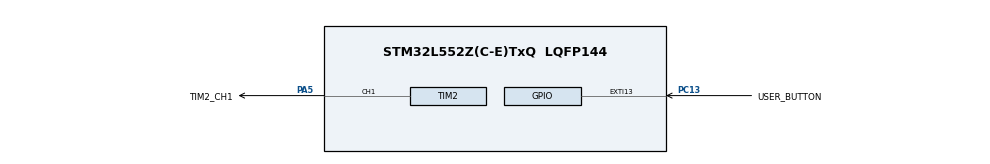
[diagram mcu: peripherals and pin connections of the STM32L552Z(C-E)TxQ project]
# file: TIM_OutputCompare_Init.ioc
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Mcu.Family=STM32L5
Mcu.Name=STM32L552Z(C-E)TxQ
Mcu.Package=LQFP144
Mcu.TrustZone=disable
NVIC.EXTI13_IRQn=true\:0\:0\:false\:false\:true\:true\:true\:true
NVIC.PriorityGroup=NVIC_PRIORITYGROUP_3
NVIC.TIM2_IRQn=true\:0\:0\:false\:false\:true\:true\:true\:true
PA5.GPIO_Label=TIM2_CH1
PA5.Signal=S_TIM2_CH1
PC13.GPIO_Label=USER_BUTTON
PC13.GPIO_ModeDefaultEXTI=GPIO_MODE_IT_FALLING
PC13.GPIO_PuPd=GPIO_PULLDOWN
PC13.Signal=GPXTI13
ProjectManager.HeapSize=0x200
ProjectManager.StackSize=0x400
ProjectManager.TargetToolchain=EWARM V8.32
RCC.ADCCLockSelection=RCC_ADCCLKSOURCE_SYSCLK
RCC.ADCFreq_Value=110000000
RCC.AHBFreq_Value=110000000
RCC.APB1Freq_Value=110000000
RCC.APB1TimFreq_Value=110000000
RCC.APB2Freq_Value=110000000
RCC.APB2TimFreq_Value=110000000
RCC.CortexFreq_Value=110000000
RCC.HCLKFreq_Value=110000000
RCC.HSE_VALUE=16000000
RCC.HSI48_VALUE=48000000
RCC.HSI_VALUE=16000000
RCC.LSE_VALUE=32768
RCC.MSI_VALUE=4000000
RCC.PLLN=55
RCC.PLLSAI1N=24
RCC.RTCClockSelection=RCC_RTCCLKSOURCE_LSE
RCC.SYSCLKFreq_VALUE=110000000
RCC.SYSCLKSource=RCC_SYSCLKSOURCE_PLLCLK
RCC.USBFreq_Value=48000000
RCC.VCOOutputFreq_Value=220000000
SH.S_TIM2_CH1.0=TIM2_CH1,Output Compare1 CH1
TIM2.AutoReloadPreload=TIM_AUTORELOAD_PRELOAD_DISABLE
TIM2.Channel-Output\ Compare1\ CH1=TIM_CHANNEL_1
TIM2.ClearInputSource=TIM_CLEARINPUTSOURCE_NONE
TIM2.ClockDivision=TIM_CLOCKDIVISION_DIV1
TIM2.CounterMode=TIM_COUNTERMODE_UP
TIM2.OC1Preload=DISABLE
TIM2.OCMode_1=TIM_OCMODE_TOGGLE
TIM2.OCPolarity_1=TIM_OCPOLARITY_HIGH
TIM2.Period=tim_period
TIM2.Prescaler=tim_prescaler
TIM2.Pulse-Output\ Compare1\ CH1=tim_pulse_value
TIM2.TIM_MasterOutputTrigger=TIM_TRGO_RESET
TIM2.TIM_MasterSlaveMode=TIM_MASTERSLAVEMODE_DISABLE
VP_ICACHE_VS_ICACHE.Mode=DirectMappedCache
VP_PWR_VS_DBSignals.Mode=DisableDeadBatterySignals
board=custom

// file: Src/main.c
/* USER CODE BEGIN Header */
/**
  ******************************************************************************
  * @file    Examples_LL/TIM/TIM_OutputCompare_Init/Src/main.c
  * @author  MCD Application Team
  * @brief   This example describes how to use a timer instance in output
  *          compare mode using the STM32L5xx TIM LL API.
  *          Peripheral initialization done using LL unitary services functions.
  ******************************************************************************
  * @attention
  *
  * Copyright (c) 2019 STMicroelectronics.
  * All rights reserved.
  *
  * This software is licensed under terms that can be found in the LICENSE file
  * in the root directory of this software component.
  * If no LICENSE file comes with this software, it is provided AS-IS.
  *
  ******************************************************************************
  */
/* USER CODE END Header */
#include "main.h"

/* USER CODE BEGIN PD */
/* Number of output compare modes */
#define TIM_OC_MODES_NB 3
/* USER CODE END PD */

/* USER CODE BEGIN PV */
/* Output compare modes */
static uint32_t aOCMode[TIM_OC_MODES_NB] = {
  LL_TIM_OCMODE_TOGGLE,
  LL_TIM_OCMODE_ACTIVE,
  LL_TIM_OCMODE_INACTIVE
};

/* Output compare mode index */
static uint8_t iOCMode = 0;

/* Compare match count */
static uint32_t uwCompareMatchCount = 0;

/* TIM2 Clock */
static uint32_t TimOutClock = 1;
static uint32_t tim_prescaler = 0;
static uint32_t tim_period = 0;
static uint32_t tim_pulse_value = 0;
/* USER CODE END PV */

void SystemClock_Config(void);
static void MX_GPIO_Init(void);
static void MX_ICACHE_Init(void);
static void MX_TIM2_Init(void);
/* USER CODE BEGIN PFP */
__STATIC_INLINE void     Configure_OCMode(uint32_t OCMode);
/* USER CODE END PFP */

int main(void)
{

  /* MCU Configuration--------------------------------------------------------*/

  /* Reset of all peripherals, Initializes the Flash interface and the Systick. */
  LL_APB2_GRP1_EnableClock(LL_APB2_GRP1_PERIPH_SYSCFG);
  LL_APB1_GRP1_EnableClock(LL_APB1_GRP1_PERIPH_PWR);

  /* System interrupt init*/
  NVIC_SetPriorityGrouping(NVIC_PRIORITYGROUP_3);

  /** Disable the internal Pull-Up in Dead Battery pins of UCPD peripheral
  */
  LL_PWR_DisableUCPDDeadBattery();

  /* Configure the system clock */
  SystemClock_Config();

  /* USER CODE BEGIN SysInit */

  /* Set the pre-scaler value to have TIM2 counter clock equal to 10 kHz */
  tim_prescaler = __LL_TIM_CALC_PSC(SystemCoreClock, 10000);

  /* Set the auto-reload value to have a counter frequency of 10 Hz */
  /* TIM2CLK = SystemCoreClock / (APB prescaler & multiplier)               */
  TimOutClock = SystemCoreClock/1;
  tim_period = __LL_TIM_CALC_ARR(TimOutClock, tim_prescaler, 10);

  /* Set output compare active/inactive delay to half of the auto-reload value */
  tim_pulse_value = tim_period / 2;

  /* USER CODE END SysInit */

  /* Initialize all configured peripherals */
  MX_GPIO_Init();
  MX_ICACHE_Init();
  MX_TIM2_Init();
  /* USER CODE BEGIN 2 */

  /**************************/
  /* TIM2 interrupts set-up */
  /**************************/
  /* Enable the capture/compare interrupt for channel 1*/
  LL_TIM_EnableIT_CC1(TIM2);

  /**********************************/
  /* Start output signal generation */
  /**********************************/
  /* Enable output channel 1 */
  LL_TIM_CC_EnableChannel(TIM2, LL_TIM_CHANNEL_CH1);

  /* Enable counter */
  LL_TIM_EnableCounter(TIM2);

  /* USER CODE END 2 */

  /* Infinite loop */
  while (1)
  {

  }
}

void SystemClock_Config(void)
{
  LL_FLASH_SetLatency(LL_FLASH_LATENCY_5);
  while(LL_FLASH_GetLatency()!= LL_FLASH_LATENCY_5)
  {
  }

  LL_PWR_SetRegulVoltageScaling(LL_PWR_REGU_VOLTAGE_SCALE0);
  LL_RCC_MSI_Enable();

   /* Wait till MSI is ready */
  while(LL_RCC_MSI_IsReady() != 1)
  {
  }

  LL_RCC_MSI_EnableRangeSelection();
  LL_RCC_MSI_SetRange(LL_RCC_MSIRANGE_6);
  LL_RCC_MSI_SetCalibTrimming(0);
  LL_RCC_PLL_ConfigDomain_SYS(LL_RCC_PLLSOURCE_MSI, LL_RCC_PLLM_DIV_1, 55, LL_RCC_PLLR_DIV_2);
  LL_RCC_PLL_EnableDomain_SYS();
  LL_RCC_PLL_Enable();

   /* Wait till PLL is ready */
  while(LL_RCC_PLL_IsReady() != 1)
  {
  }

   /* Intermediate AHB prescaler 2 when target frequency clock is higher than 80 MHz */
   LL_RCC_SetAHBPrescaler(LL_RCC_SYSCLK_DIV_2);

  LL_RCC_SetSysClkSource(LL_RCC_SYS_CLKSOURCE_PLL);

   /* Wait till System clock is ready */
  while(LL_RCC_GetSysClkSource() != LL_RCC_SYS_CLKSOURCE_STATUS_PLL)
  {
  }

  /* Insure 1us transition state at intermediate medium speed clock*/
  for (__IO uint32_t i = (RCC_MAX_FREQUENCY_MHZ >> 1); i !=0; i--);

  LL_RCC_SetAHBPrescaler(LL_RCC_SYSCLK_DIV_1);
  LL_RCC_SetAPB1Prescaler(LL_RCC_APB1_DIV_1);
  LL_RCC_SetAPB2Prescaler(LL_RCC_APB2_DIV_1);

  LL_Init1msTick(110000000);

  LL_SetSystemCoreClock(110000000);
}

static void MX_ICACHE_Init(void)
{

  /** Enable instruction cache in 1-way (direct mapped cache)
  */
  LL_ICACHE_SetMode(LL_ICACHE_1WAY);
  LL_ICACHE_Enable();

}

static void MX_TIM2_Init(void)
{

  LL_TIM_InitTypeDef TIM_InitStruct = {0};
  LL_TIM_OC_InitTypeDef TIM_OC_InitStruct = {0};

  LL_GPIO_InitTypeDef GPIO_InitStruct = {0};

  /* Peripheral clock enable */
  LL_APB1_GRP1_EnableClock(LL_APB1_GRP1_PERIPH_TIM2);

  /* TIM2 interrupt Init */
  NVIC_SetPriority(TIM2_IRQn, NVIC_EncodePriority(NVIC_GetPriorityGrouping(),0, 0));
  NVIC_EnableIRQ(TIM2_IRQn);

  TIM_InitStruct.Prescaler = tim_prescaler;
  TIM_InitStruct.CounterMode = LL_TIM_COUNTERMODE_UP;
  TIM_InitStruct.Autoreload = tim_period;
  TIM_InitStruct.ClockDivision = LL_TIM_CLOCKDIVISION_DIV1;
  LL_TIM_Init(TIM2, &TIM_InitStruct);
  LL_TIM_DisableARRPreload(TIM2);
  TIM_OC_InitStruct.OCMode = LL_TIM_OCMODE_TOGGLE;
  TIM_OC_InitStruct.OCState = LL_TIM_OCSTATE_DISABLE;
  TIM_OC_InitStruct.OCNState = LL_TIM_OCSTATE_DISABLE;
  TIM_OC_InitStruct.CompareValue = tim_pulse_value;
  TIM_OC_InitStruct.OCPolarity = LL_TIM_OCPOLARITY_HIGH;
  LL_TIM_OC_Init(TIM2, LL_TIM_CHANNEL_CH1, &TIM_OC_InitStruct);
  LL_TIM_OC_DisableFast(TIM2, LL_TIM_CHANNEL_CH1);
  LL_TIM_SetTriggerOutput(TIM2, LL_TIM_TRGO_RESET);
  LL_TIM_DisableMasterSlaveMode(TIM2);
  LL_AHB2_GRP1_EnableClock(LL_AHB2_GRP1_PERIPH_GPIOA);
  /**TIM2 GPIO Configuration
  PA5   ------> TIM2_CH1
  */
  GPIO_InitStruct.Pin = TIM2_CH1_Pin;
  GPIO_InitStruct.Mode = LL_GPIO_MODE_ALTERNATE;
  GPIO_InitStruct.Speed = LL_GPIO_SPEED_FREQ_LOW;
  GPIO_InitStruct.OutputType = LL_GPIO_OUTPUT_PUSHPULL;
  GPIO_InitStruct.Pull = LL_GPIO_PULL_NO;
  GPIO_InitStruct.Alternate = LL_GPIO_AF_1;
  LL_GPIO_Init(TIM2_CH1_GPIO_Port, &GPIO_InitStruct);

}

static void MX_GPIO_Init(void)
{
  LL_EXTI_InitTypeDef EXTI_InitStruct = {0};

  /* GPIO Ports Clock Enable */
  LL_AHB2_GRP1_EnableClock(LL_AHB2_GRP1_PERIPH_GPIOC);
  LL_AHB2_GRP1_EnableClock(LL_AHB2_GRP1_PERIPH_GPIOA);

  /**/
  LL_EXTI_SetEXTISource(LL_EXTI_EXTI_PORTC, LL_EXTI_EXTI_LINE13);

  /**/
  EXTI_InitStruct.Line_0_31 = LL_EXTI_LINE_13;
  EXTI_InitStruct.Line_32_63 = LL_EXTI_LINE_NONE;
  EXTI_InitStruct.LineCommand = ENABLE;
  EXTI_InitStruct.Mode = LL_EXTI_MODE_IT;
  EXTI_InitStruct.Trigger = LL_EXTI_TRIGGER_FALLING;
  LL_EXTI_Init(&EXTI_InitStruct);

  /**/
  LL_GPIO_SetPinPull(USER_BUTTON_GPIO_Port, USER_BUTTON_Pin, LL_GPIO_PULL_DOWN);

  /**/
  LL_GPIO_SetPinMode(USER_BUTTON_GPIO_Port, USER_BUTTON_Pin, LL_GPIO_MODE_INPUT);

  /* EXTI interrupt init*/
  NVIC_SetPriority(EXTI13_IRQn, NVIC_EncodePriority(NVIC_GetPriorityGrouping(),0, 0));
  NVIC_EnableIRQ(EXTI13_IRQn);

}

/* USER CODE BEGIN 4 */

/**
  * @brief  Changes the output compare mode.
  * @param  None
  * @retval None
  */
__STATIC_INLINE void Configure_OCMode(uint32_t OCMode)
{
  /* Disable the counter */
  LL_TIM_DisableCounter(TIM2);

  /* Reset the counter */
  LL_TIM_SetCounter(TIM2, 0);

  /* Reset the compare match count */
  uwCompareMatchCount = 0;

  /* Set the output level (active v.s. inactive) according to the new OC mode */
  switch (OCMode)
  {
    case LL_TIM_OCMODE_TOGGLE:
    case LL_TIM_OCMODE_ACTIVE:
      /* Set the output channel to its inactive level (LOW)*/
      LL_TIM_OC_SetMode(TIM2, LL_TIM_CHANNEL_CH1, LL_TIM_OCMODE_FORCED_INACTIVE);
      break;

    case LL_TIM_OCMODE_INACTIVE:
      /* Set the output channel to its active level (HIGH)*/
      LL_TIM_OC_SetMode(TIM2, LL_TIM_CHANNEL_CH1, LL_TIM_OCMODE_FORCED_ACTIVE);
      break;

    default:
      break;
  }

  /* Update the output channel mode */
  LL_TIM_OC_SetMode(TIM2, LL_TIM_CHANNEL_CH1, OCMode);

  /* Re-enable the counter */
  LL_TIM_EnableCounter(TIM2);
}

/******************************************************************************/
/*   USER IRQ HANDLER TREATMENT                                               */
/******************************************************************************/
/**
  * @brief  User button interrupt processing
  * @param  None
  * @retval None
  */
void UserButton_Callback(void)
{
  /* Set new OC mode */
  iOCMode = (iOCMode + 1) % TIM_OC_MODES_NB;

  /* Switch to next OC mode */
  Configure_OCMode(aOCMode[iOCMode]);
}

/**
  * @brief  Timer capture/compare interrupt processing
  * @note   The capture/compare interrupt is generated whatever the compare
  *         mode is (as long as the timer counter is enabled).
  * @param  None
  * @retval None
  */
void TimerCaptureCompare_Callback(void)
{
   /* Upon compare match, the counter value  should be equal to the */
   /* capture/compare register value */
  if(LL_TIM_GetCounter(TIM2) == LL_TIM_OC_GetCompareCH1(TIM2))
  {
    /* Increment the compare match count */
    uwCompareMatchCount++;
  }
}

/* USER CODE END 4 */

void Error_Handler(void)
{
  while(1)
  {
  }
}
